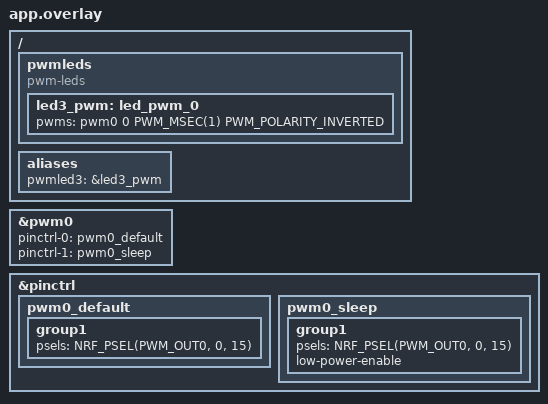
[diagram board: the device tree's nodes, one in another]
/* app.overlay for nrf52840dk_nrf52840: drive LED3 (P0.15) with PWM0 CH0 */

&pwm0 {
    status = "okay";
    pinctrl-0 = <&pwm0_default>;
    pinctrl-1 = <&pwm0_sleep>;
    pinctrl-names = "default", "sleep";
};

&pinctrl {
    /* Route PWM0 channel 0 to P0.15 (LED3 on the DK) */
    pwm0_default: pwm0_default {
        group1 {
            psels = <NRF_PSEL(PWM_OUT0, 0, 15)>;
        };
    };
    pwm0_sleep: pwm0_sleep {
        group1 {
            psels = <NRF_PSEL(PWM_OUT0, 0, 15)>;
            low-power-enable;
        };
    };
};

/* Define a PWM-backed LED and alias it as pwmled3 */
 / {
    pwmleds: pwmleds {
        compatible = "pwm-leds";

        /* pwms = <&pwm0 channel period flags>; 1 kHz, inverted (active-low LED) */
        led3_pwm: led_pwm_0 {
            pwms = <&pwm0 0 PWM_MSEC(1) PWM_POLARITY_INVERTED>;
        };
    };

    aliases {
        pwmled3 = &led3_pwm;
    };
};
